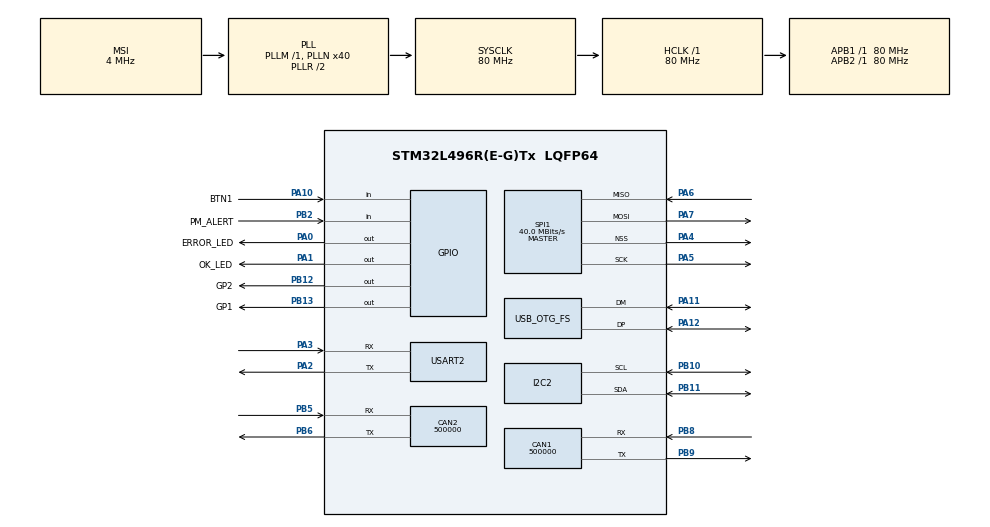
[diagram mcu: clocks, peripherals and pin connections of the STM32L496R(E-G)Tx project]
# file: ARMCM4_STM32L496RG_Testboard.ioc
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CAN1.BS1=CAN_BS1_8TQ
CAN1.CalculateBaudRate=500000
CAN1.CalculateTimeBit=2000
CAN1.CalculateTimeQuantum=200.0
CAN1.Mode=CAN_MODE_LOOPBACK
CAN2.BS1=CAN_BS1_8TQ
CAN2.CalculateBaudRate=500000
CAN2.CalculateTimeBit=2000
CAN2.CalculateTimeQuantum=200.0
FREERTOS.Tasks01=defaultTask,24,128,StartDefaultTask,Default,NULL,Dynamic,NULL,NULL
I2C2.Timing=0x10909CEC
Mcu.Family=STM32L4
Mcu.Name=STM32L496R(E-G)Tx
Mcu.Package=LQFP64
NVIC.CAN1_RX0_IRQn=true\:5\:0\:false\:false\:true\:true\:true\:true\:true
NVIC.OTG_FS_IRQn=true\:5\:0\:false\:false\:true\:true\:false\:true\:true
NVIC.PriorityGroup=NVIC_PRIORITYGROUP_4
NVIC.TIM1_TRG_COM_TIM17_IRQn=true\:15\:0\:false\:false\:true\:false\:false\:true\:true
NVIC.TimeBase=TIM1_TRG_COM_TIM17_IRQn
NVIC.TimeBaseIP=TIM17
PA0.GPIO_Label=ERROR_LED
PA0.Signal=GPIO_Output
PA1.GPIO_Label=OK_LED
PA1.Signal=GPIO_Output
PA10.GPIO_Label=BTN1
PA10.Signal=GPIO_Input
PA11.Mode=Device_Only
PA11.Signal=USB_OTG_FS_DM
PA12.Mode=Device_Only
PA12.Signal=USB_OTG_FS_DP
PA13\ (JTMS/SWDIO).Mode=Trace_Asynchronous_SW
PA13\ (JTMS/SWDIO).Signal=SYS_JTMS-SWDIO
PA14\ (JTCK/SWCLK).Mode=Trace_Asynchronous_SW
PA14\ (JTCK/SWCLK).Signal=SYS_JTCK-SWCLK
PA2.Mode=Asynchronous
PA2.Signal=USART2_TX
PA3.Mode=Asynchronous
PA3.Signal=USART2_RX
PA4.Mode=NSS_Signal_Hard_Output
PA4.Signal=SPI1_NSS
PA5.Mode=Full_Duplex_Master
PA5.Signal=SPI1_SCK
PA6.Mode=Full_Duplex_Master
PA6.Signal=SPI1_MISO
PA7.Mode=Full_Duplex_Master
PA7.Signal=SPI1_MOSI
PB10.Mode=I2C
PB10.Signal=I2C2_SCL
PB11.Mode=I2C
PB11.Signal=I2C2_SDA
PB12.GPIO_Label=GP2
PB12.Signal=GPIO_Output
PB13.GPIO_Label=GP1
PB13.Signal=GPIO_Output
PB2.GPIO_Label=PM_ALERT
PB2.Signal=GPIO_Input
PB3\ (JTDO/TRACESWO).Mode=Trace_Asynchronous_SW
PB3\ (JTDO/TRACESWO).Signal=SYS_JTDO-SWO
PB5.Mode=CAN_Activate
PB5.Signal=CAN2_RX
PB6.Mode=CAN_Activate
PB6.Signal=CAN2_TX
PB8.Mode=CAN_Activate
PB8.Signal=CAN1_RX
PB9.Mode=CAN_Activate
PB9.Signal=CAN1_TX
PH0-OSC_IN\ (PH0).Mode=HSE-External-Oscillator
PH0-OSC_IN\ (PH0).Signal=RCC_OSC_IN
PH1-OSC_OUT\ (PH1).Mode=HSE-External-Oscillator
PH1-OSC_OUT\ (PH1).Signal=RCC_OSC_OUT
ProjectManager.HeapSize=0x200
ProjectManager.StackSize=0x400
ProjectManager.TargetToolchain=Makefile
RCC.ADCFreq_Value=48000000
RCC.AHBFreq_Value=80000000
RCC.APB1Freq_Value=80000000
RCC.APB1TimFreq_Value=80000000
RCC.APB2Freq_Value=80000000
RCC.APB2TimFreq_Value=80000000
RCC.CortexFreq_Value=80000000
RCC.HCLKFreq_Value=80000000
RCC.HSE_VALUE=8000000
RCC.HSI48_VALUE=48000000
RCC.HSI_VALUE=16000000
RCC.LSE_VALUE=32768
RCC.MSI_VALUE=4000000
RCC.PLLN=40
RCC.PLLSAI1N=24
RCC.SYSCLKFreq_VALUE=80000000
RCC.SYSCLKSource=RCC_SYSCLKSOURCE_PLLCLK
RCC.USBFreq_Value=48000000
RCC.VCOOutputFreq_Value=160000000
SPI1.CalculateBaudRate=40.0 MBits/s
SPI1.Direction=SPI_DIRECTION_2LINES
SPI1.Mode=SPI_MODE_MASTER
SPI1.VirtualNSS=VM_NSSHARD
SPI1.VirtualType=VM_MASTER
TIM3.Channel-Output\ Compare1\ No\ Output=TIM_CHANNEL_1
TIM3.Period=65535
TIM3.Prescaler=80-1
USART2.VirtualMode-Asynchronous=VM_ASYNC
USB_DEVICE.CLASS_NAME_FS=CDC
USB_DEVICE.VirtualMode=Cdc
USB_DEVICE.VirtualModeFS=Cdc_FS
USB_OTG_FS.VirtualMode=Device_Only
VP_FREERTOS_VS_CMSIS_V2.Mode=CMSIS_V2
VP_SYS_VS_tim17.Mode=TIM17
VP_TIM3_VS_no_output1.Mode=Output Compare1 No Output
VP_USB_DEVICE_VS_USB_DEVICE_CDC_FS.Mode=CDC_FS
board=custom

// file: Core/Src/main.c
/* USER CODE BEGIN Header */
/**
  ******************************************************************************
  * @file           : main.c
  * @brief          : Main program body
  ******************************************************************************
  * @attention
  *
  * Copyright (c) 2023 STMicroelectronics.
  * All rights reserved.
  *
  * This software is licensed under terms that can be found in the LICENSE file
  * in the root directory of this software component.
  * If no LICENSE file comes with this software, it is provided AS-IS.
  *
  ******************************************************************************
  */
/* USER CODE END Header */
#include "main.h"
#include "cmsis_os.h"
#include "usb_device.h"

/* USER CODE BEGIN Includes */
#include "user.h"
/* USER CODE END Includes */

CAN_HandleTypeDef hcan1;
CAN_HandleTypeDef hcan2;

TIM_HandleTypeDef htim3;

/* Definitions for defaultTask */
osThreadId_t defaultTaskHandle;
const osThreadAttr_t defaultTask_attributes = {
  .name = "defaultTask",
  .stack_size = 128 * 4,
  .priority = (osPriority_t) osPriorityNormal,
};
/* USER CODE BEGIN PV */
uint32_t utick = 0;
/* USER CODE END PV */

void SystemClock_Config(void);
static void MX_GPIO_Init(void);
static void MX_CAN1_Init(void);
static void MX_CAN2_Init(void);
static void MX_I2C2_Init(void);
static void MX_SPI1_Init(void);
static void MX_TIM3_Init(void);
static void MX_USART2_UART_Init(void);
void StartDefaultTask(void *argument);

int main(void)
{

  /* MCU Configuration--------------------------------------------------------*/

  /* Reset of all peripherals, Initializes the Flash interface and the Systick. */
  HAL_Init();

  /* Configure the system clock */
  SystemClock_Config();

  /* Initialize all configured peripherals */
  MX_GPIO_Init();
  MX_CAN1_Init();
  MX_CAN2_Init();
  MX_I2C2_Init();
  MX_SPI1_Init();
  MX_TIM3_Init();
  MX_USART2_UART_Init();
  /* USER CODE BEGIN 2 */
  UserSetup();
  /* USER CODE END 2 */

  /* Init scheduler */
  osKernelInitialize();

  /* Create the thread(s) */
  /* creation of defaultTask */
  defaultTaskHandle = osThreadNew(StartDefaultTask, NULL, &defaultTask_attributes);

  /* Start scheduler */
  osKernelStart();

  /* We should never get here as control is now taken by the scheduler */
  /* Infinite loop */
  while (1)
  {

  }
}

void SystemClock_Config(void)
{
  RCC_OscInitTypeDef RCC_OscInitStruct = {0};
  RCC_ClkInitTypeDef RCC_ClkInitStruct = {0};

  /** Configure the main internal regulator output voltage
  */
  if (HAL_PWREx_ControlVoltageScaling(PWR_REGULATOR_VOLTAGE_SCALE1) != HAL_OK)
  {
    Error_Handler();
  }

  /** Initializes the RCC Oscillators according to the specified parameters
  * in the RCC_OscInitTypeDef structure.
  */
  RCC_OscInitStruct.OscillatorType = RCC_OSCILLATORTYPE_LSE|RCC_OSCILLATORTYPE_MSI;
  RCC_OscInitStruct.LSEState = RCC_LSE_OFF;
  RCC_OscInitStruct.MSIState = RCC_MSI_ON;
  RCC_OscInitStruct.MSICalibrationValue = 0;
  RCC_OscInitStruct.MSIClockRange = RCC_MSIRANGE_6;
  RCC_OscInitStruct.PLL.PLLState = RCC_PLL_ON;
  RCC_OscInitStruct.PLL.PLLSource = RCC_PLLSOURCE_MSI;
  RCC_OscInitStruct.PLL.PLLM = 1;
  RCC_OscInitStruct.PLL.PLLN = 40;
  RCC_OscInitStruct.PLL.PLLP = RCC_PLLP_DIV2;
  RCC_OscInitStruct.PLL.PLLQ = RCC_PLLQ_DIV2;
  RCC_OscInitStruct.PLL.PLLR = RCC_PLLR_DIV2;
  if (HAL_RCC_OscConfig(&RCC_OscInitStruct) != HAL_OK)
  {
    Error_Handler();
  }

  /** Initializes the CPU, AHB and APB buses clocks
  */
  RCC_ClkInitStruct.ClockType = RCC_CLOCKTYPE_HCLK|RCC_CLOCKTYPE_SYSCLK
                              |RCC_CLOCKTYPE_PCLK1|RCC_CLOCKTYPE_PCLK2;
  RCC_ClkInitStruct.SYSCLKSource = RCC_SYSCLKSOURCE_PLLCLK;
  RCC_ClkInitStruct.AHBCLKDivider = RCC_SYSCLK_DIV1;
  RCC_ClkInitStruct.APB1CLKDivider = RCC_HCLK_DIV1;
  RCC_ClkInitStruct.APB2CLKDivider = RCC_HCLK_DIV1;

  if (HAL_RCC_ClockConfig(&RCC_ClkInitStruct, FLASH_LATENCY_4) != HAL_OK)
  {
    Error_Handler();
  }

  /** Enable MSI Auto calibration
  */
  HAL_RCCEx_EnableMSIPLLMode();
}

static void MX_CAN1_Init(void)
{

  hcan1.Instance = CAN1;
  hcan1.Init.Prescaler = 16;
  hcan1.Init.Mode = CAN_MODE_LOOPBACK;
  hcan1.Init.SyncJumpWidth = CAN_SJW_1TQ;
  hcan1.Init.TimeSeg1 = CAN_BS1_8TQ;
  hcan1.Init.TimeSeg2 = CAN_BS2_1TQ;
  hcan1.Init.TimeTriggeredMode = DISABLE;
  hcan1.Init.AutoBusOff = DISABLE;
  hcan1.Init.AutoWakeUp = DISABLE;
  hcan1.Init.AutoRetransmission = DISABLE;
  hcan1.Init.ReceiveFifoLocked = DISABLE;
  hcan1.Init.TransmitFifoPriority = DISABLE;
  if (HAL_CAN_Init(&hcan1) != HAL_OK)
  {
    Error_Handler();
  }

}

static void MX_CAN2_Init(void)
{

  hcan2.Instance = CAN2;
  hcan2.Init.Prescaler = 16;
  hcan2.Init.Mode = CAN_MODE_NORMAL;
  hcan2.Init.SyncJumpWidth = CAN_SJW_1TQ;
  hcan2.Init.TimeSeg1 = CAN_BS1_8TQ;
  hcan2.Init.TimeSeg2 = CAN_BS2_1TQ;
  hcan2.Init.TimeTriggeredMode = DISABLE;
  hcan2.Init.AutoBusOff = DISABLE;
  hcan2.Init.AutoWakeUp = DISABLE;
  hcan2.Init.AutoRetransmission = DISABLE;
  hcan2.Init.ReceiveFifoLocked = DISABLE;
  hcan2.Init.TransmitFifoPriority = DISABLE;
  if (HAL_CAN_Init(&hcan2) != HAL_OK)
  {
    Error_Handler();
  }

}

static void MX_I2C2_Init(void)
{

  LL_I2C_InitTypeDef I2C_InitStruct = {0};

  LL_GPIO_InitTypeDef GPIO_InitStruct = {0};
  RCC_PeriphCLKInitTypeDef PeriphClkInit = {0};

  /** Initializes the peripherals clock
  */
  PeriphClkInit.PeriphClockSelection = RCC_PERIPHCLK_I2C2;
  PeriphClkInit.I2c2ClockSelection = RCC_I2C2CLKSOURCE_PCLK1;
  if (HAL_RCCEx_PeriphCLKConfig(&PeriphClkInit) != HAL_OK)
  {
    Error_Handler();
  }

  LL_AHB2_GRP1_EnableClock(LL_AHB2_GRP1_PERIPH_GPIOB);
  /**I2C2 GPIO Configuration
  PB10   ------> I2C2_SCL
  PB11   ------> I2C2_SDA
  */
  GPIO_InitStruct.Pin = LL_GPIO_PIN_10|LL_GPIO_PIN_11;
  GPIO_InitStruct.Mode = LL_GPIO_MODE_ALTERNATE;
  GPIO_InitStruct.Speed = LL_GPIO_SPEED_FREQ_VERY_HIGH;
  GPIO_InitStruct.OutputType = LL_GPIO_OUTPUT_OPENDRAIN;
  GPIO_InitStruct.Pull = LL_GPIO_PULL_NO;
  GPIO_InitStruct.Alternate = LL_GPIO_AF_4;
  LL_GPIO_Init(GPIOB, &GPIO_InitStruct);

  /* Peripheral clock enable */
  LL_APB1_GRP1_EnableClock(LL_APB1_GRP1_PERIPH_I2C2);

  /** I2C Initialization
  */
  LL_I2C_EnableAutoEndMode(I2C2);
  LL_I2C_DisableOwnAddress2(I2C2);
  LL_I2C_DisableGeneralCall(I2C2);
  LL_I2C_EnableClockStretching(I2C2);
  I2C_InitStruct.PeripheralMode = LL_I2C_MODE_I2C;
  I2C_InitStruct.Timing = 0x10909CEC;
  I2C_InitStruct.AnalogFilter = LL_I2C_ANALOGFILTER_ENABLE;
  I2C_InitStruct.DigitalFilter = 0;
  I2C_InitStruct.OwnAddress1 = 0;
  I2C_InitStruct.TypeAcknowledge = LL_I2C_ACK;
  I2C_InitStruct.OwnAddrSize = LL_I2C_OWNADDRESS1_7BIT;
  LL_I2C_Init(I2C2, &I2C_InitStruct);
  LL_I2C_SetOwnAddress2(I2C2, 0, LL_I2C_OWNADDRESS2_NOMASK);

}

static void MX_SPI1_Init(void)
{

  LL_SPI_InitTypeDef SPI_InitStruct = {0};

  LL_GPIO_InitTypeDef GPIO_InitStruct = {0};

  /* Peripheral clock enable */
  LL_APB2_GRP1_EnableClock(LL_APB2_GRP1_PERIPH_SPI1);

  LL_AHB2_GRP1_EnableClock(LL_AHB2_GRP1_PERIPH_GPIOA);
  /**SPI1 GPIO Configuration
  PA4   ------> SPI1_NSS
  PA5   ------> SPI1_SCK
  PA6   ------> SPI1_MISO
  PA7   ------> SPI1_MOSI
  */
  GPIO_InitStruct.Pin = LL_GPIO_PIN_4|LL_GPIO_PIN_5|LL_GPIO_PIN_6|LL_GPIO_PIN_7;
  GPIO_InitStruct.Mode = LL_GPIO_MODE_ALTERNATE;
  GPIO_InitStruct.Speed = LL_GPIO_SPEED_FREQ_VERY_HIGH;
  GPIO_InitStruct.OutputType = LL_GPIO_OUTPUT_PUSHPULL;
  GPIO_InitStruct.Pull = LL_GPIO_PULL_NO;
  GPIO_InitStruct.Alternate = LL_GPIO_AF_5;
  LL_GPIO_Init(GPIOA, &GPIO_InitStruct);

  /* SPI1 parameter configuration*/
  SPI_InitStruct.TransferDirection = LL_SPI_FULL_DUPLEX;
  SPI_InitStruct.Mode = LL_SPI_MODE_MASTER;
  SPI_InitStruct.DataWidth = LL_SPI_DATAWIDTH_4BIT;
  SPI_InitStruct.ClockPolarity = LL_SPI_POLARITY_LOW;
  SPI_InitStruct.ClockPhase = LL_SPI_PHASE_1EDGE;
  SPI_InitStruct.NSS = LL_SPI_NSS_HARD_OUTPUT;
  SPI_InitStruct.BaudRate = LL_SPI_BAUDRATEPRESCALER_DIV2;
  SPI_InitStruct.BitOrder = LL_SPI_MSB_FIRST;
  SPI_InitStruct.CRCCalculation = LL_SPI_CRCCALCULATION_DISABLE;
  SPI_InitStruct.CRCPoly = 7;
  LL_SPI_Init(SPI1, &SPI_InitStruct);
  LL_SPI_SetStandard(SPI1, LL_SPI_PROTOCOL_MOTOROLA);
  LL_SPI_EnableNSSPulseMgt(SPI1);

}

static void MX_TIM3_Init(void)
{

  TIM_MasterConfigTypeDef sMasterConfig = {0};
  TIM_OC_InitTypeDef sConfigOC = {0};

  htim3.Instance = TIM3;
  htim3.Init.Prescaler = 80-1;
  htim3.Init.CounterMode = TIM_COUNTERMODE_UP;
  htim3.Init.Period = 65535;
  htim3.Init.ClockDivision = TIM_CLOCKDIVISION_DIV1;
  htim3.Init.AutoReloadPreload = TIM_AUTORELOAD_PRELOAD_DISABLE;
  if (HAL_TIM_OC_Init(&htim3) != HAL_OK)
  {
    Error_Handler();
  }
  sMasterConfig.MasterOutputTrigger = TIM_TRGO_RESET;
  sMasterConfig.MasterSlaveMode = TIM_MASTERSLAVEMODE_DISABLE;
  if (HAL_TIMEx_MasterConfigSynchronization(&htim3, &sMasterConfig) != HAL_OK)
  {
    Error_Handler();
  }
  sConfigOC.OCMode = TIM_OCMODE_TIMING;
  sConfigOC.Pulse = 0;
  sConfigOC.OCPolarity = TIM_OCPOLARITY_HIGH;
  sConfigOC.OCFastMode = TIM_OCFAST_DISABLE;
  if (HAL_TIM_OC_ConfigChannel(&htim3, &sConfigOC, TIM_CHANNEL_1) != HAL_OK)
  {
    Error_Handler();
  }

}

static void MX_USART2_UART_Init(void)
{

  LL_USART_InitTypeDef USART_InitStruct = {0};

  LL_GPIO_InitTypeDef GPIO_InitStruct = {0};
  RCC_PeriphCLKInitTypeDef PeriphClkInit = {0};

  /** Initializes the peripherals clock
  */
  PeriphClkInit.PeriphClockSelection = RCC_PERIPHCLK_USART2;
  PeriphClkInit.Usart2ClockSelection = RCC_USART2CLKSOURCE_PCLK1;
  if (HAL_RCCEx_PeriphCLKConfig(&PeriphClkInit) != HAL_OK)
  {
    Error_Handler();
  }

  /* Peripheral clock enable */
  LL_APB1_GRP1_EnableClock(LL_APB1_GRP1_PERIPH_USART2);

  LL_AHB2_GRP1_EnableClock(LL_AHB2_GRP1_PERIPH_GPIOA);
  /**USART2 GPIO Configuration
  PA2   ------> USART2_TX
  PA3   ------> USART2_RX
  */
  GPIO_InitStruct.Pin = LL_GPIO_PIN_2|LL_GPIO_PIN_3;
  GPIO_InitStruct.Mode = LL_GPIO_MODE_ALTERNATE;
  GPIO_InitStruct.Speed = LL_GPIO_SPEED_FREQ_VERY_HIGH;
  GPIO_InitStruct.OutputType = LL_GPIO_OUTPUT_PUSHPULL;
  GPIO_InitStruct.Pull = LL_GPIO_PULL_NO;
  GPIO_InitStruct.Alternate = LL_GPIO_AF_7;
  LL_GPIO_Init(GPIOA, &GPIO_InitStruct);

  USART_InitStruct.BaudRate = 115200;
  USART_InitStruct.DataWidth = LL_USART_DATAWIDTH_8B;
  USART_InitStruct.StopBits = LL_USART_STOPBITS_1;
  USART_InitStruct.Parity = LL_USART_PARITY_NONE;
  USART_InitStruct.TransferDirection = LL_USART_DIRECTION_TX_RX;
  USART_InitStruct.HardwareFlowControl = LL_USART_HWCONTROL_NONE;
  USART_InitStruct.OverSampling = LL_USART_OVERSAMPLING_16;
  LL_USART_Init(USART2, &USART_InitStruct);
  LL_USART_ConfigAsyncMode(USART2);
  LL_USART_Enable(USART2);

}

static void MX_GPIO_Init(void)
{
  LL_GPIO_InitTypeDef GPIO_InitStruct = {0};

  /* GPIO Ports Clock Enable */
  LL_AHB2_GRP1_EnableClock(LL_AHB2_GRP1_PERIPH_GPIOH);
  LL_AHB2_GRP1_EnableClock(LL_AHB2_GRP1_PERIPH_GPIOA);
  LL_AHB2_GRP1_EnableClock(LL_AHB2_GRP1_PERIPH_GPIOB);

  /**/
  LL_GPIO_ResetOutputPin(GPIOA, ERROR_LED_Pin|OK_LED_Pin);

  /**/
  LL_GPIO_ResetOutputPin(GPIOB, GP2_Pin|GP1_Pin);

  /**/
  GPIO_InitStruct.Pin = ERROR_LED_Pin|OK_LED_Pin;
  GPIO_InitStruct.Mode = LL_GPIO_MODE_OUTPUT;
  GPIO_InitStruct.Speed = LL_GPIO_SPEED_FREQ_LOW;
  GPIO_InitStruct.OutputType = LL_GPIO_OUTPUT_PUSHPULL;
  GPIO_InitStruct.Pull = LL_GPIO_PULL_NO;
  LL_GPIO_Init(GPIOA, &GPIO_InitStruct);

  /**/
  GPIO_InitStruct.Pin = PM_ALERT_Pin;
  GPIO_InitStruct.Mode = LL_GPIO_MODE_INPUT;
  GPIO_InitStruct.Pull = LL_GPIO_PULL_NO;
  LL_GPIO_Init(PM_ALERT_GPIO_Port, &GPIO_InitStruct);

  /**/
  GPIO_InitStruct.Pin = GP2_Pin|GP1_Pin;
  GPIO_InitStruct.Mode = LL_GPIO_MODE_OUTPUT;
  GPIO_InitStruct.Speed = LL_GPIO_SPEED_FREQ_LOW;
  GPIO_InitStruct.OutputType = LL_GPIO_OUTPUT_PUSHPULL;
  GPIO_InitStruct.Pull = LL_GPIO_PULL_NO;
  LL_GPIO_Init(GPIOB, &GPIO_InitStruct);

  /**/
  GPIO_InitStruct.Pin = BTN1_Pin;
  GPIO_InitStruct.Mode = LL_GPIO_MODE_INPUT;
  GPIO_InitStruct.Pull = LL_GPIO_PULL_NO;
  LL_GPIO_Init(BTN1_GPIO_Port, &GPIO_InitStruct);

}

void StartDefaultTask(void *argument)
{
  /* init code for USB_DEVICE */
  MX_USB_DEVICE_Init();
  for(;;)
  {
    osDelay(1);
  }
}

void HAL_TIM_PeriodElapsedCallback(TIM_HandleTypeDef *htim)
{
  if (htim->Instance == TIM17) {
    HAL_IncTick();
  }
}

void Error_Handler(void)
{
  __disable_irq();
  while (1)
  {
  }
}
